# STM32L0x1 register map
File version: 1.6
CPU: CM0+ r0p0, little endian, MPU, no FPU, 2 interrupt priority bits
Registers are 32-bit, read-write, reset 0x0 unless marked. A register's access mark holds for its fields unless they carry their own. Offsets are from the block's base; [hi:lo] are bit positions; {n}, {i} and the like mark numbered series; 'fields as' and 'values as' point back to an identical list.

## DBG — Debug support
Base 0x40015800
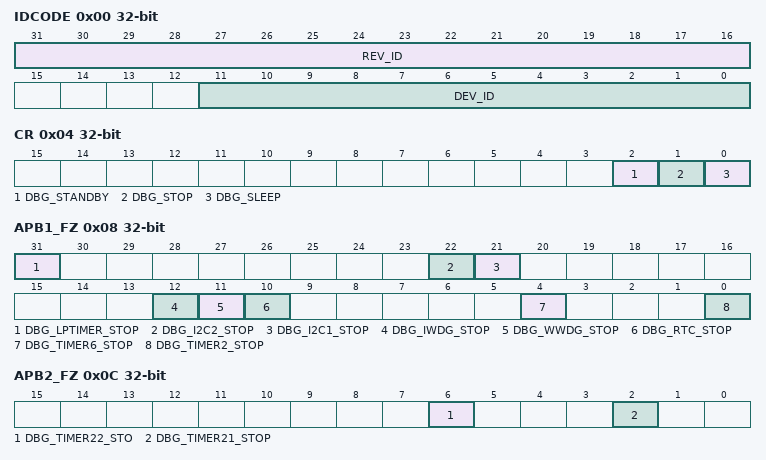
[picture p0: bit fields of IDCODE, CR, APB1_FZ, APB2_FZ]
0x00 IDCODE ro — MCU Device ID Code Register
  [31:16] REV_ID — Revision Identifier
  [11:0] DEV_ID — Device Identifier
0x04 CR — Debug MCU Configuration Register
  [2] DBG_STANDBY — Debug Standby Mode
    0=Disabled (Debug Standby Mode Disabled); 1=Enabled (Debug Standby Mode Enabled)
  [1] DBG_STOP — Debug Stop Mode
    0=Disabled (Debug Stop Mode Disabled); 1=Enabled (Debug Stop Mode Enabled)
  [0] DBG_SLEEP — Debug Sleep Mode
    0=Disabled (Debug Sleep Mode Disabled); 1=Enabled (Debug Sleep Mode Enabled)
0x08 APB1_FZ — APB Low Freeze Register
  [31] DBG_LPTIMER_STOP — LPTIM1 counter stopped when core is halted
    0=Continue (LPTIM1 counter clock is fed even if the core is halted); 1=Stop (LPTIM1 counter clock is stopped when the core is halted)
  [22] DBG_I2C2_STOP — I2C2 SMBUS timeout mode stopped when core is halted
    0=NormalMode (Same behavior as in normal mode); 1=SMBusTimeoutFrozen (I2C3 SMBUS timeout is frozen)
  [21] DBG_I2C1_STOP — I2C1 SMBUS timeout mode stopped when core is halted
    values as DBG_I2C2_STOP
  [12] DBG_IWDG_STOP — Debug Independent Wachdog stopped when Core is halted
    0=Continue (The independent watchdog counter clock continues even if the core is halted); 1=Stop (The independent watchdog counter clock is stopped when the core is halted)
  [11] DBG_WWDG_STOP — Debug Window Wachdog stopped when Core is halted
    0=Continue (The window watchdog counter clock continues even if the core is halted); 1=Stop (The window watchdog counter clock is stopped when the core is halted)
  [10] DBG_RTC_STOP — Debug RTC stopped when Core is halted
    0=Continue (The clock of the RTC counter is fed even if the core is halted); 1=Stop (The clock of the RTC counter is stopped when the core is halted)
  [4] DBG_TIMER6_STOP — Debug Timer 6 stopped when Core is halted
    0=Continue (The counter clock of TIMx is fed even if the core is halted); 1=Stop (The counter clock of TIMx is stopped when the core is halted)
  [0] DBG_TIMER2_STOP — Debug Timer 2 stopped when Core is halted
    values as DBG_TIMER6_STOP
0x0C APB2_FZ — APB High Freeze Register
  [6] DBG_TIMER22_STO — Debug Timer 22 stopped when Core is halted
  [2] DBG_TIMER21_STOP — Debug Timer 21 stopped when Core is halted
    values as APB1_FZ.DBG_TIMER6_STOP

## TIM6 — Basic-timers
Base 0x40001000
Same registers: TIM7 0x40001400
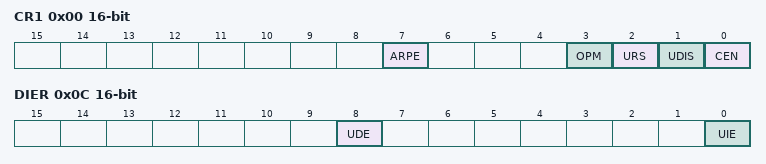
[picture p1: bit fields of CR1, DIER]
0x00 CR1 16-bit — control register 1
  [7] ARPE — Auto-reload preload enable
    0=Disabled (TIMx_APRR register is not buffered); 1=Enabled (TIMx_APRR register is buffered)
  [3] OPM — One-pulse mode
    0=Disabled (Counter is not stopped at update event); 1=Enabled (Counter stops counting at the next update event (clearing the CEN bit))
  [2] URS — Update request source
    0=AnyEvent (Any of counter overflow/underflow, setting UG, or update through slave mode, generates an update interrupt or DMA request); 1=CounterOnly (Only counter overflow/underflow generates an update interrupt or DMA request)
  [1] UDIS — Update disable
    0=Enabled (Update event enabled); 1=Disabled (Update event disabled)
  [0] CEN — Counter enable
    0=Disabled (Counter disabled); 1=Enabled (Counter enabled)
0x04 CR2 16-bit — control register 2
  [6:4] MMS — Master mode selection
    0=Reset (Use UG bit from TIMx_EGR register); 1=Enable (Use CNT bit from TIMx_CEN register); 2=Update (Use the update event)
0x0C DIER 16-bit — DMA/Interrupt enable register
  [8] UDE — Update DMA request enable
    0=Disabled (Update DMA request disabled); 1=Enabled (Update DMA request enabled)
  [0] UIE — Update interrupt enable
    0=Disabled (Update interrupt disabled); 1=Enabled (Update interrupt enabled)
0x10 SR 16-bit — status register
  [0] UIF write-0-clears — Update interrupt flag
    on read: 0=NoUpdateOccurred; 1=UpdatePending (Update interrupt pending) | on write: 0=Clear flag
0x14 EGR 16-bit wo — event generation register
  [0] UG — Update generation
    1=Update (Re-initializes the timer counter and generates an update of the registers.)
0x24 CNT 16-bit — counter
  [15:0] CNT — Low counter value
0x28 PSC 16-bit — prescaler
  [15:0] PSC — Prescaler value
0x2C ARR 16-bit reset 0xFFFF — auto-reload register
  [15:0] ARR — Low Auto-reload value

## NVIC — Nested Vectored Interrupt Controller
Base 0xE000E100
0x00 ISER — Interrupt Set Enable Register
  [31:0] SETENA
0x80 ICER — Interrupt Clear Enable Register
  [31:0] CLRENA
0x100 ISPR — Interrupt Set-Pending Register
  [31:0] SETPEND
0x180 ICPR — Interrupt Clear-Pending Register
  [31:0] CLRPEND
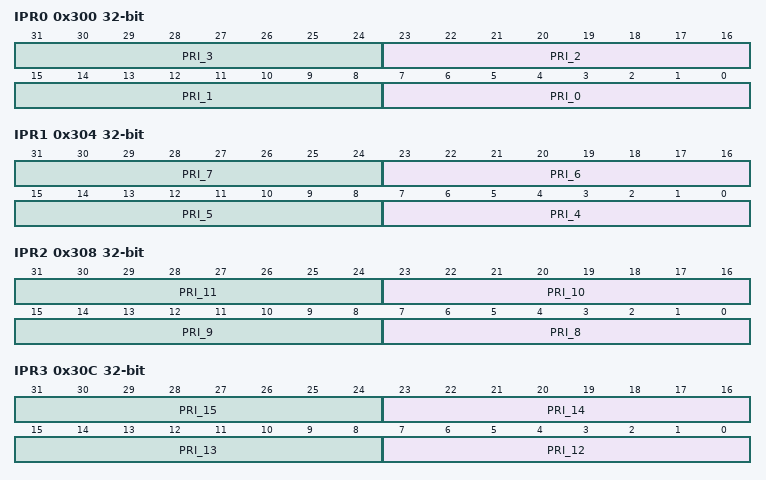
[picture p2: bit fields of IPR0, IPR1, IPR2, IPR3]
0x300 IPR0 — Interrupt Priority Register 0
  [8n+7:8n] PRI_{n} (n=0..3) — priority for interrupt {n}
0x304 IPR1 — Interrupt Priority Register 1
  [8n-25:8n-32] PRI_{n} (n=4..7) — priority for interrupt n
0x308 IPR2 — Interrupt Priority Register 2
  [8n-57:8n-64] PRI_{n} (n=8..11) — priority for interrupt n
0x30C IPR3 — Interrupt Priority Register 3
  [8n-89:8n-96] PRI_{n} (n=12..15) — priority for interrupt n
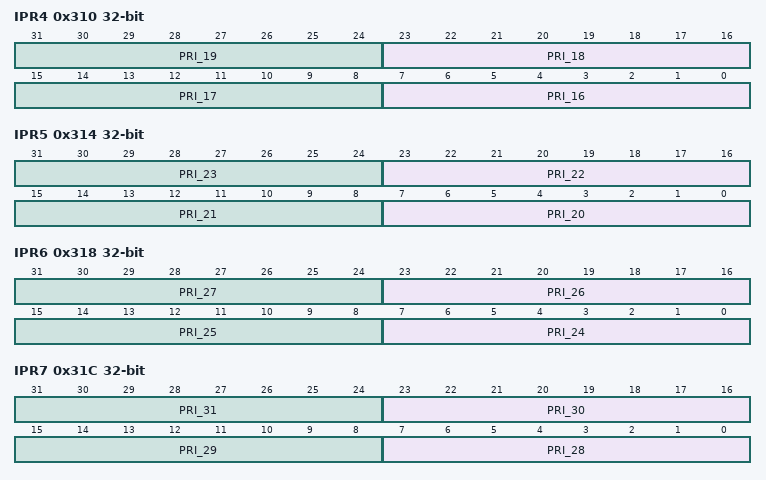
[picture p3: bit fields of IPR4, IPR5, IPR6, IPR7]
0x310 IPR4 — Interrupt Priority Register 4
  [8n-121:8n-128] PRI_{n} (n=16..19) — priority for interrupt n
0x314 IPR5 — Interrupt Priority Register 5
  [8n-153:8n-160] PRI_{n} (n=20..23) — priority for interrupt n
0x318 IPR6 — Interrupt Priority Register 6
  [8n-185:8n-192] PRI_{n} (n=24..27) — priority for interrupt n
0x31C IPR7 — Interrupt Priority Register 7
  [8n-217:8n-224] PRI_{n} (n=28..31) — priority for interrupt n
